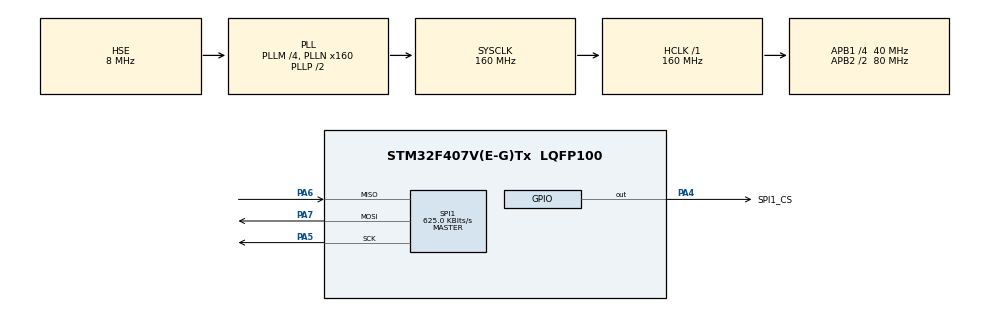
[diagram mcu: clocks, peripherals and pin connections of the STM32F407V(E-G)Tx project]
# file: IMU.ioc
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Mcu.Family=STM32F4
Mcu.Name=STM32F407V(E-G)Tx
Mcu.Package=LQFP100
NVIC.PriorityGroup=NVIC_PRIORITYGROUP_4
PA4.GPIO_Label=SPI1_CS
PA4.Signal=GPIO_Output
PA5.Mode=Full_Duplex_Master
PA5.Signal=SPI1_SCK
PA6.Mode=Full_Duplex_Master
PA6.Signal=SPI1_MISO
PA7.Mode=Full_Duplex_Master
PA7.Signal=SPI1_MOSI
PC14-OSC32_IN.Mode=LSE-External-Oscillator
PC14-OSC32_IN.Signal=RCC_OSC32_IN
PC15-OSC32_OUT.Mode=LSE-External-Oscillator
PC15-OSC32_OUT.Signal=RCC_OSC32_OUT
PH0-OSC_IN.Mode=HSE-External-Oscillator
PH0-OSC_IN.Signal=RCC_OSC_IN
PH1-OSC_OUT.Mode=HSE-External-Oscillator
PH1-OSC_OUT.Signal=RCC_OSC_OUT
ProjectManager.HeapSize=0x200
ProjectManager.StackSize=0x400
ProjectManager.TargetToolchain=MDK-ARM V5.27
RCC.48MHZClocksFreq_Value=80000000
RCC.AHBFreq_Value=160000000
RCC.APB1CLKDivider=RCC_HCLK_DIV4
RCC.APB1Freq_Value=40000000
RCC.APB1TimFreq_Value=80000000
RCC.APB2CLKDivider=RCC_HCLK_DIV2
RCC.APB2Freq_Value=80000000
RCC.APB2TimFreq_Value=160000000
RCC.CortexFreq_Value=160000000
RCC.HCLKFreq_Value=160000000
RCC.HSE_VALUE=8000000
RCC.HSI_VALUE=16000000
RCC.PLLM=4
RCC.PLLN=160
RCC.PLLSourceVirtual=RCC_PLLSOURCE_HSE
RCC.SYSCLKFreq_VALUE=160000000
RCC.SYSCLKSource=RCC_SYSCLKSOURCE_PLLCLK
RCC.VCOOutputFreq_Value=320000000
SPI1.BaudRatePrescaler=SPI_BAUDRATEPRESCALER_128
SPI1.CLKPhase=SPI_PHASE_2EDGE
SPI1.CLKPolarity=SPI_POLARITY_HIGH
SPI1.CalculateBaudRate=625.0 KBits/s
SPI1.DataSize=SPI_DATASIZE_16BIT
SPI1.Direction=SPI_DIRECTION_2LINES
SPI1.Mode=SPI_MODE_MASTER
SPI1.VirtualType=VM_MASTER
board=custom

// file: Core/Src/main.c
/* USER CODE BEGIN Header */
/**
  ******************************************************************************
  * @file           : main.c
  * @brief          : Main program body
  ******************************************************************************
  * @attention
  *
  * <h2><center>&copy; Copyright (c) 2021 STMicroelectronics.
  * All rights reserved.</center></h2>
  *
  * This software component is licensed by ST under BSD 3-Clause license,
  * the "License"; You may not use this file except in compliance with the
  * License. You may obtain a copy of the License at:
  *                        opensource.org/licenses/BSD-3-Clause
  *
  ******************************************************************************
  */
/* USER CODE END Header */
#include "main.h"
#include "spi.h"
#include "gpio.h"

/* USER CODE BEGIN Includes */
#include "imu.h"
/* USER CODE END Includes */

void SystemClock_Config(void);

int main(void)
{

  /* MCU Configuration--------------------------------------------------------*/

  /* Reset of all peripherals, Initializes the Flash interface and the Systick. */
  HAL_Init();

  /* Configure the system clock */
  SystemClock_Config();

  /* Initialize all configured peripherals */
  MX_GPIO_Init();
  MX_SPI1_Init();
  /* USER CODE BEGIN 2 */
  HAL_Delay(200);

  ADIS16467_t imu;
  imu.GPIOx = SPI1_CS_GPIO_Port;
  imu.GPIO_PIN = SPI1_CS_Pin;
  imu.hspi = &hspi1;
  ADIS16467_Init(&imu);

  while (ADIS16467_Check(&imu) == 0)
  {
    ADIS16467_Init(&imu);
    HAL_Delay(1000);
  }
  ADIS16467_DeviceInfo(&imu);
  /* USER CODE END 2 */

  /* Infinite loop */
  while (1)
  {

    /* USER CODE BEGIN 3 */

    //single read #### not usable temporarily
    /*ADIS16467_Read_Accel(&imu);
    ADIS16467_Read_Gyro(&imu);
    ADIS16467_Read_Temp(&imu);*/

    //burst read
    ADIS16467_Burst_Read(&imu);

    //printf("Acc of x, y, z: %f, %f, %f\n", imu.Ax, imu.Ay, imu.Az);
    //printf("Gyro of x, y, z: %f, %f, %f\n", imu.Gx, imu.Gy, imu.Gz);
    HAL_Delay(500);
  }
  /* USER CODE END 3 */
}

void SystemClock_Config(void)
{
  RCC_OscInitTypeDef RCC_OscInitStruct = {0};
  RCC_ClkInitTypeDef RCC_ClkInitStruct = {0};

  /** Configure the main internal regulator output voltage
  */
  __HAL_RCC_PWR_CLK_ENABLE();
  __HAL_PWR_VOLTAGESCALING_CONFIG(PWR_REGULATOR_VOLTAGE_SCALE1);
  /** Initializes the RCC Oscillators according to the specified parameters
  * in the RCC_OscInitTypeDef structure.
  */
  RCC_OscInitStruct.OscillatorType = RCC_OSCILLATORTYPE_HSE;
  RCC_OscInitStruct.HSEState = RCC_HSE_ON;
  RCC_OscInitStruct.PLL.PLLState = RCC_PLL_ON;
  RCC_OscInitStruct.PLL.PLLSource = RCC_PLLSOURCE_HSE;
  RCC_OscInitStruct.PLL.PLLM = 4;
  RCC_OscInitStruct.PLL.PLLN = 160;
  RCC_OscInitStruct.PLL.PLLP = RCC_PLLP_DIV2;
  RCC_OscInitStruct.PLL.PLLQ = 4;
  if (HAL_RCC_OscConfig(&RCC_OscInitStruct) != HAL_OK)
  {
    Error_Handler();
  }
  /** Initializes the CPU, AHB and APB buses clocks
  */
  RCC_ClkInitStruct.ClockType = RCC_CLOCKTYPE_HCLK | RCC_CLOCKTYPE_SYSCLK | RCC_CLOCKTYPE_PCLK1 | RCC_CLOCKTYPE_PCLK2;
  RCC_ClkInitStruct.SYSCLKSource = RCC_SYSCLKSOURCE_PLLCLK;
  RCC_ClkInitStruct.AHBCLKDivider = RCC_SYSCLK_DIV1;
  RCC_ClkInitStruct.APB1CLKDivider = RCC_HCLK_DIV4;
  RCC_ClkInitStruct.APB2CLKDivider = RCC_HCLK_DIV2;

  if (HAL_RCC_ClockConfig(&RCC_ClkInitStruct, FLASH_LATENCY_5) != HAL_OK)
  {
    Error_Handler();
  }
}

void Error_Handler(void)
{
  __disable_irq();
  while (1)
  {
  }
}

/************************ (C) COPYRIGHT STMicroelectronics *****END OF FILE****/
